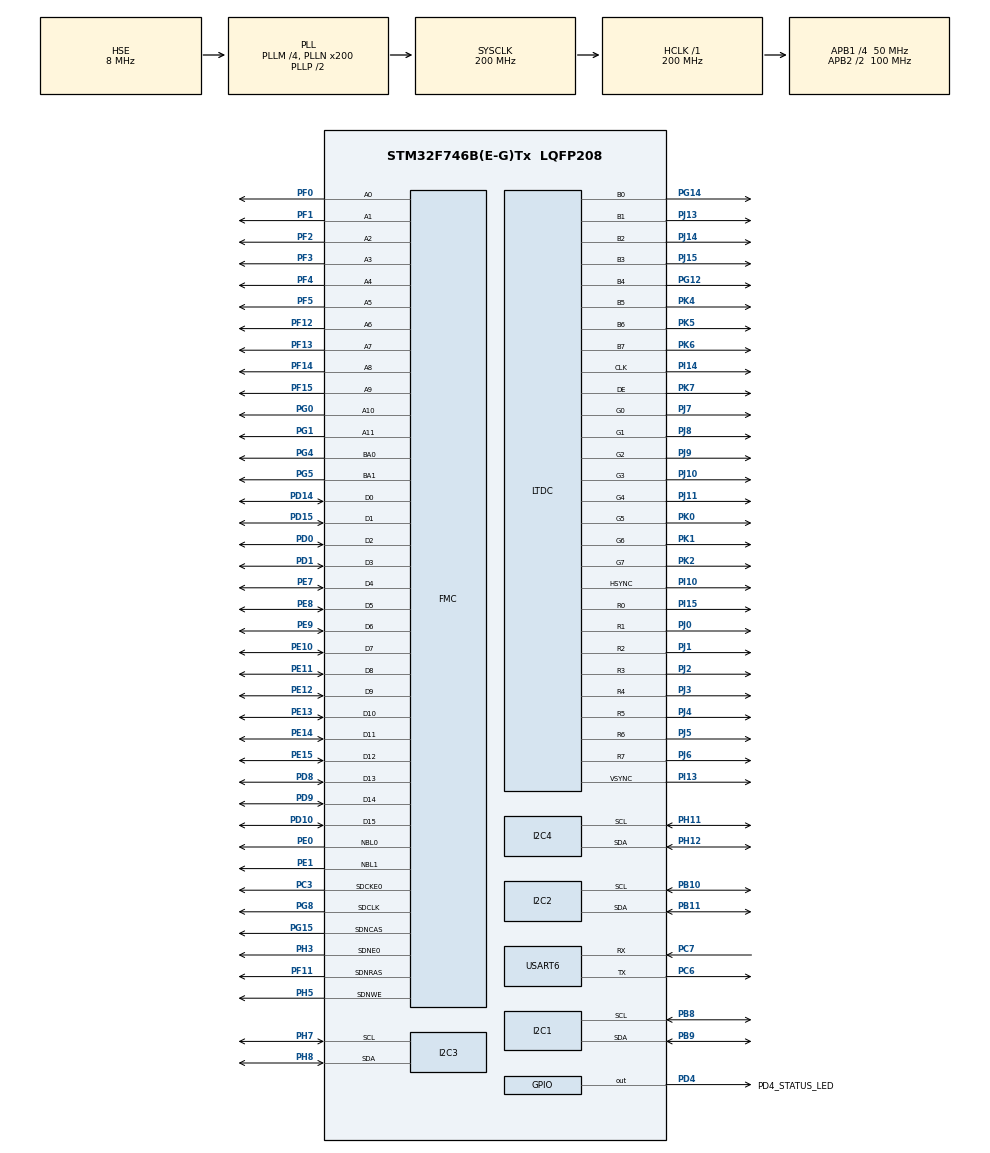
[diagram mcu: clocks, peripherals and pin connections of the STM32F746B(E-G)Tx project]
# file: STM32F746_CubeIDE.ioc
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SH.FMC_D7_DA7.0=FMC_D7,sd-16b-d1
PK5.Signal=LTDC_B6
PJ9.Mode=RGB888
PH12.Signal=I2C4_SDA
FMC.RCDDelay1=2
FMC.SDClockPeriod1=FMC_SDRAM_CLOCK_PERIOD_2
SH.FMC_A0.0=FMC_A0,12b-sda1
PB10.Mode=I2C
PK0.Mode=RGB888
PG4.Signal=FMC_A14_BA0
PG8.Signal=FMC_SDCLK
PG0.Signal=FMC_A10
FMC.LoadToActiveDelay1=2
PK1.Signal=LTDC_G6
SH.FMC_D5_DA5.0=FMC_D5,sd-16b-d1
RCC.SYSCLKSource=RCC_SYSCLKSOURCE_PLLCLK
PJ10.Signal=LTDC_G3
SH.FMC_A15_BA1.0=FMC_BA1,FourSdramBanks1
SH.FMC_D9_DA9.0=FMC_D9,sd-16b-d1
PH5.Signal=FMC_SDNWE
SH.FMC_SDNWE.0=FMC_SDNWE,12b-sda1
I2C4.Timing=0x00C0EAFF
SH.FMC_D11_DA11.0=FMC_D11,sd-16b-d1
PJ5.Mode=RGB888
PD4.Signal=GPIO_Output
RCC.APB2TimFreq_Value=200000000
PC7.Signal=USART6_RX
PH1/OSC_OUT.Signal=RCC_OSC_OUT
PC3.Signal=FMC_SDCKE0
PD0.Signal=FMC_D2_DA2
PD8.Signal=FMC_D13_DA13
USART6.VirtualMode-Asynchronous=VM_ASYNC
PE1.Signal=FMC_NBL1
PJ14.Mode=RGB888
PG14.Mode=RGB888
FMC.SelfRefreshTime1=4
LTDC.PixelFormat_L0=LTDC_PIXEL_FORMAT_RGB565
PK7.Mode=RGB888
PE9.Signal=FMC_D6_DA6
PJ2.Mode=RGB888
SH.FMC_A2.0=FMC_A2,12b-sda1
SH.FMC_D1_DA1.0=FMC_D1,sd-16b-d1
PF3.Signal=FMC_A3
PE10.Signal=FMC_D7_DA7
LTDC.HSync=1
PJ14.Signal=LTDC_B2
Mcu.Package=LQFP208
PB9.Signal=I2C1_SDA
PH12.Mode=I2C
PH11.Mode=I2C
PJ4.Signal=LTDC_R5
FMC.WriteRecoveryTime1=3
SH.FMC_A1.0=FMC_A1,12b-sda1
RCC.APB2CLKDivider=RCC_HCLK_DIV2
SH.FMC_SDCLK.0=FMC_SDCLK,12b-sda1
LTDC.VSync=10
PF14.Signal=FMC_A8
RCC.APB1TimFreq_Value=100000000
VP_DMA2D_VS_DMA2D.Mode=DMA2D_Activate
FMC.RowCycleDelay1=7
PJ13.Mode=RGB888
PH8.Mode=I2C
PJ1.Mode=RGB888
PD15.Signal=FMC_D1_DA1
SH.FMC_D3_DA3.0=FMC_D3,sd-16b-d1
PG12.Signal=LTDC_B4
PK4.Signal=LTDC_B5
SH.FMC_A4.0=FMC_A4,12b-sda1
PG5.Signal=FMC_A15_BA1
SH.FMC_D10_DA10.0=FMC_D10,sd-16b-d1
PI10.Mode=RGB888
PC6.Signal=USART6_TX
PD1.Signal=FMC_D3_DA3
RCC.APB1CLKDivider=RCC_HCLK_DIV4
PJ11.Signal=LTDC_G4
LTDC.ImageWidth_L0=480
PD10.Signal=FMC_D15_DA15
PJ6.Mode=RGB888
SH.FMC_A3.0=FMC_A3,12b-sda1
PJ7.Signal=LTDC_G0
PJ3.Signal=LTDC_R4
FMC.CASLatency1=FMC_SDRAM_CAS_LATENCY_3
PB11.Mode=I2C
SH.FMC_D15_DA15.0=FMC_D15,sd-16b-d1
PC6.Mode=Asynchronous
I2C1.Timing=0x00C0EAFF
PB10.Signal=I2C2_SCL
PJ15.Signal=LTDC_B3
FMC.ReadBurst1=FMC_SDRAM_RBURST_ENABLE
SH.FMC_A6.0=FMC_A6,12b-sda1
PE14.Signal=FMC_D11_DA11
PE15.Signal=FMC_D12_DA12
PE8.Signal=FMC_D5_DA5
PF13.Signal=FMC_A7
SH.FMC_SDNCAS.0=FMC_SDNCAS,12b-sda1
PJ15.Mode=RGB888
PK4.Mode=RGB888
SH.FMC_A5.0=FMC_A5,12b-sda1
LTDC.Alpha_L0=255
PJ8.Signal=LTDC_G1
ProjectManager.HeapSize=0x200
PJ10.Mode=RGB888
NVIC.PriorityGroup=NVIC_PRIORITYGROUP_4
PB8.Mode=I2C
PJ4.Mode=RGB888
PF4.Signal=FMC_A4
Mcu.Family=STM32F7
PC3.Mode=SdramChipSelect1_1
PK7.Signal=LTDC_DE
LTDC.BlendingFactor1_L0=LTDC_BLENDING_FACTOR1_PAxCA
SH.FMC_A8.0=FMC_A8,12b-sda1
RCC.CortexFreq_Value=200000000
SH.FMC_D14_DA14.0=FMC_D14,sd-16b-d1
LTDC.HBP=43
I2C2.Timing=0x00C0EAFF
SH.FMC_NBL0.0=FMC_NBL0,Sd2ByteEnable1
SH.FMC_D6_DA6.0=FMC_D6,sd-16b-d1
SH.FMC_A14_BA0.0=FMC_BA0,FourSdramBanks1
SH.FMC_A11.0=FMC_A11,12b-sda1
PB11.Signal=I2C2_SDA
PG15.Signal=FMC_SDNCAS
ProjectManager.StackSize=0x400
PH3.Mode=SdramChipSelect1_1
PJ6.Signal=LTDC_R7
SH.FMC_A7.0=FMC_A7,12b-sda1
PJ2.Signal=LTDC_R3
PH0/OSC_IN.Mode=HSE-External-Oscillator
RCC.HCLKFreq_Value=200000000
SH.FMC_NBL1.0=FMC_NBL1,Sd2ByteEnable1
LTDC.WindowX1_L0=480
PF12.Signal=FMC_A6
PK2.Mode=RGB888
PI13.Signal=LTDC_VSYNC
SH.FMC_A10.0=FMC_A10,12b-sda1
RCC.AHBFreq_Value=200000000
RCC.HSE_VALUE=8000000
SH.FMC_D8_DA8.0=FMC_D8,sd-16b-d1
FMC.ExitSelfRefreshDelay1=7
FMC.RPDelay1=2
PI14.Mode=RGB888
SH.FMC_D2_DA2.0=FMC_D2,sd-16b-d1
LTDC.VBP=12
PE13.Signal=FMC_D10_DA10
PK6.Mode=RGB888
PF11.Signal=FMC_SDNRAS
LTDC.HFP=8
LTDC.BlendingFactor2_L0=LTDC_BLENDING_FACTOR2_PAxCA
SH.FMC_SDNRAS.0=FMC_SDNRAS,12b-sda1
LTDC.ActiveW=480
PH1/OSC_OUT.Mode=HSE-External-Oscillator
PH7.Mode=I2C
PJ0.Mode=RGB888
SH.FMC_D0_DA0.0=FMC_D0,sd-16b-d1
PJ9.Signal=LTDC_G2
NVIC.LTDC_ER_IRQn=true\:0\:0\:false\:false\:true\:true\:true
SH.FMC_A9.0=FMC_A9,12b-sda1
PJ1.Signal=LTDC_R2
SH.FMC_D4_DA4.0=FMC_D4,sd-16b-d1
PF5.Signal=FMC_A5
I2C3.Timing=0x00C0EAFF
PH7.Signal=I2C3_SCL
PJ7.Mode=RGB888
PF0.Signal=FMC_A0
PE7.Signal=FMC_D4_DA4
PI15.Mode=RGB888
PK1.Mode=RGB888
RCC.PLLSourceVirtual=RCC_PLLSOURCE_HSE
PK6.Signal=LTDC_B7
NVIC.LTDC_IRQn=true\:0\:0\:false\:false\:true\:true\:true
PK2.Signal=LTDC_G7
LTDC.VFP=4
LTDC.WindowY1_L0=272
PJ8.Mode=RGB888
PH11.Signal=I2C4_SCL
PG1.Signal=FMC_A11
PI14.Signal=LTDC_CLK
PI10.Signal=LTDC_HSYNC
PD9.Signal=FMC_D14_DA14
PJ11.Mode=RGB888
ProjectManager.TargetToolchain=STM32CubeIDE
SH.FMC_D13_DA13.0=FMC_D13,sd-16b-d1
LTDC.ActiveH=272
PH8.Signal=I2C3_SDA
PB9.Mode=I2C
PF2.Signal=FMC_A2
RCC.USBFreq_Value=200000000
PE11.Signal=FMC_D8_DA8
RCC.LSE_VALUE=32768
PK0.Signal=LTDC_G5
PK5.Mode=RGB888
PG14.Signal=LTDC_B0
board=custom
PG12.Mode=RGB888
RCC.VCOOutputFreq_Value=400000000
PJ3.Mode=RGB888
PH0/OSC_IN.Signal=RCC_OSC_IN
RCC.APB2Freq_Value=100000000
LTDC.Layers=0
PD4.GPIO_Label=PD4_STATUS_LED
SH.FMC_D12_DA12.0=FMC_D12,sd-16b-d1
PF15.Signal=FMC_A9
PF1.Signal=FMC_A1
PI13.Mode=RGB888
PJ0.Signal=LTDC_R1
Mcu.Name=STM32F746B(E-G)Tx
PE0.Signal=FMC_NBL0
PE12.Signal=FMC_D9_DA9
PD14.Signal=FMC_D0_DA0
RCC.SYSCLKFreq_VALUE=200000000
PJ5.Signal=LTDC_R6
RCC.HSI_VALUE=16000000
PH3.Signal=FMC_SDNE0
RCC.PLLM=4
RCC.PLLN=200
PI15.Signal=LTDC_R0
PB8.Signal=I2C1_SCL
PC7.Mode=Asynchronous
RCC.APB1Freq_Value=50000000
VP_CRC_VS_CRC.Mode=CRC_Activate
LTDC.ImageHeight_L0=272
PJ13.Signal=LTDC_B1

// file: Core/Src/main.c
/* USER CODE BEGIN Header */
/**
  ******************************************************************************
  * @file           : main.c
  * @brief          : Main program body
  ******************************************************************************
  * @attention
  *
  * <h2><center>&copy; Copyright (c) 2021 STMicroelectronics.
  * All rights reserved.</center></h2>
  *
  * This software component is licensed by ST under BSD 3-Clause license,
  * the "License"; You may not use this file except in compliance with the
  * License. You may obtain a copy of the License at:
  *                        opensource.org/licenses/BSD-3-Clause
  *
  ******************************************************************************
  */
/* USER CODE END Header */
#include "main.h"

CRC_HandleTypeDef hcrc;

DMA2D_HandleTypeDef hdma2d;

I2C_HandleTypeDef hi2c1;
I2C_HandleTypeDef hi2c2;
I2C_HandleTypeDef hi2c3;
I2C_HandleTypeDef hi2c4;

LTDC_HandleTypeDef hltdc;

UART_HandleTypeDef huart6;

SDRAM_HandleTypeDef hsdram1;

void SystemClock_Config(void);
static void MX_GPIO_Init(void);
static void MX_CRC_Init(void);
static void MX_DMA2D_Init(void);
static void MX_LTDC_Init(void);
static void MX_I2C1_Init(void);
static void MX_I2C2_Init(void);
static void MX_I2C3_Init(void);
static void MX_I2C4_Init(void);
static void MX_USART6_UART_Init(void);
static void MX_FMC_Init(void);

int main(void)
{

  /* MCU Configuration--------------------------------------------------------*/

  /* Reset of all peripherals, Initializes the Flash interface and the Systick. */
  HAL_Init();

  /* Configure the system clock */
  SystemClock_Config();

  /* Initialize all configured peripherals */
  MX_GPIO_Init();
  MX_CRC_Init();
  MX_DMA2D_Init();
  MX_LTDC_Init();
  MX_I2C1_Init();
  MX_I2C2_Init();
  MX_I2C3_Init();
  MX_I2C4_Init();
  MX_USART6_UART_Init();
  MX_FMC_Init();

  /* Infinite loop */
  /* USER CODE BEGIN WHILE */
  while (1)
  {
	  HAL_GPIO_TogglePin(PD4_STATUS_LED_GPIO_Port, PD4_STATUS_LED_Pin);
	  HAL_Delay(500);
    /* USER CODE END WHILE */

  }
}

void SystemClock_Config(void)
{
  RCC_OscInitTypeDef RCC_OscInitStruct = {0};
  RCC_ClkInitTypeDef RCC_ClkInitStruct = {0};
  RCC_PeriphCLKInitTypeDef PeriphClkInitStruct = {0};

  /** Configure the main internal regulator output voltage
  */
  __HAL_RCC_PWR_CLK_ENABLE();
  __HAL_PWR_VOLTAGESCALING_CONFIG(PWR_REGULATOR_VOLTAGE_SCALE1);
  /** Initializes the RCC Oscillators according to the specified parameters
  * in the RCC_OscInitTypeDef structure.
  */
  RCC_OscInitStruct.OscillatorType = RCC_OSCILLATORTYPE_HSE;
  RCC_OscInitStruct.HSEState = RCC_HSE_ON;
  RCC_OscInitStruct.PLL.PLLState = RCC_PLL_ON;
  RCC_OscInitStruct.PLL.PLLSource = RCC_PLLSOURCE_HSE;
  RCC_OscInitStruct.PLL.PLLM = 4;
  RCC_OscInitStruct.PLL.PLLN = 200;
  RCC_OscInitStruct.PLL.PLLP = RCC_PLLP_DIV2;
  RCC_OscInitStruct.PLL.PLLQ = 2;
  if (HAL_RCC_OscConfig(&RCC_OscInitStruct) != HAL_OK)
  {
    Error_Handler();
  }
  /** Activate the Over-Drive mode
  */
  if (HAL_PWREx_EnableOverDrive() != HAL_OK)
  {
    Error_Handler();
  }
  /** Initializes the CPU, AHB and APB buses clocks
  */
  RCC_ClkInitStruct.ClockType = RCC_CLOCKTYPE_HCLK|RCC_CLOCKTYPE_SYSCLK
                              |RCC_CLOCKTYPE_PCLK1|RCC_CLOCKTYPE_PCLK2;
  RCC_ClkInitStruct.SYSCLKSource = RCC_SYSCLKSOURCE_PLLCLK;
  RCC_ClkInitStruct.AHBCLKDivider = RCC_SYSCLK_DIV1;
  RCC_ClkInitStruct.APB1CLKDivider = RCC_HCLK_DIV4;
  RCC_ClkInitStruct.APB2CLKDivider = RCC_HCLK_DIV2;

  if (HAL_RCC_ClockConfig(&RCC_ClkInitStruct, FLASH_LATENCY_6) != HAL_OK)
  {
    Error_Handler();
  }
  PeriphClkInitStruct.PeriphClockSelection = RCC_PERIPHCLK_LTDC|RCC_PERIPHCLK_USART6
                              |RCC_PERIPHCLK_I2C1|RCC_PERIPHCLK_I2C2
                              |RCC_PERIPHCLK_I2C3|RCC_PERIPHCLK_I2C4;
  PeriphClkInitStruct.PLLSAI.PLLSAIN = 192;
  PeriphClkInitStruct.PLLSAI.PLLSAIR = 2;
  PeriphClkInitStruct.PLLSAI.PLLSAIQ = 2;
  PeriphClkInitStruct.PLLSAI.PLLSAIP = RCC_PLLSAIP_DIV2;
  PeriphClkInitStruct.PLLSAIDivQ = 1;
  PeriphClkInitStruct.PLLSAIDivR = RCC_PLLSAIDIVR_2;
  PeriphClkInitStruct.Usart6ClockSelection = RCC_USART6CLKSOURCE_PCLK2;
  PeriphClkInitStruct.I2c1ClockSelection = RCC_I2C1CLKSOURCE_PCLK1;
  PeriphClkInitStruct.I2c2ClockSelection = RCC_I2C2CLKSOURCE_PCLK1;
  PeriphClkInitStruct.I2c3ClockSelection = RCC_I2C3CLKSOURCE_PCLK1;
  PeriphClkInitStruct.I2c4ClockSelection = RCC_I2C4CLKSOURCE_PCLK1;
  if (HAL_RCCEx_PeriphCLKConfig(&PeriphClkInitStruct) != HAL_OK)
  {
    Error_Handler();
  }
}

static void MX_CRC_Init(void)
{

  hcrc.Instance = CRC;
  hcrc.Init.DefaultPolynomialUse = DEFAULT_POLYNOMIAL_ENABLE;
  hcrc.Init.DefaultInitValueUse = DEFAULT_INIT_VALUE_ENABLE;
  hcrc.Init.InputDataInversionMode = CRC_INPUTDATA_INVERSION_NONE;
  hcrc.Init.OutputDataInversionMode = CRC_OUTPUTDATA_INVERSION_DISABLE;
  hcrc.InputDataFormat = CRC_INPUTDATA_FORMAT_BYTES;
  if (HAL_CRC_Init(&hcrc) != HAL_OK)
  {
    Error_Handler();
  }

}

static void MX_DMA2D_Init(void)
{

  hdma2d.Instance = DMA2D;
  hdma2d.Init.Mode = DMA2D_M2M;
  hdma2d.Init.ColorMode = DMA2D_OUTPUT_ARGB8888;
  hdma2d.Init.OutputOffset = 0;
  hdma2d.LayerCfg[1].InputOffset = 0;
  hdma2d.LayerCfg[1].InputColorMode = DMA2D_INPUT_ARGB8888;
  hdma2d.LayerCfg[1].AlphaMode = DMA2D_NO_MODIF_ALPHA;
  hdma2d.LayerCfg[1].InputAlpha = 0;
  if (HAL_DMA2D_Init(&hdma2d) != HAL_OK)
  {
    Error_Handler();
  }
  if (HAL_DMA2D_ConfigLayer(&hdma2d, 1) != HAL_OK)
  {
    Error_Handler();
  }

}

static void MX_I2C1_Init(void)
{

  hi2c1.Instance = I2C1;
  hi2c1.Init.Timing = 0x00C0EAFF;
  hi2c1.Init.OwnAddress1 = 0;
  hi2c1.Init.AddressingMode = I2C_ADDRESSINGMODE_7BIT;
  hi2c1.Init.DualAddressMode = I2C_DUALADDRESS_DISABLE;
  hi2c1.Init.OwnAddress2 = 0;
  hi2c1.Init.OwnAddress2Masks = I2C_OA2_NOMASK;
  hi2c1.Init.GeneralCallMode = I2C_GENERALCALL_DISABLE;
  hi2c1.Init.NoStretchMode = I2C_NOSTRETCH_DISABLE;
  if (HAL_I2C_Init(&hi2c1) != HAL_OK)
  {
    Error_Handler();
  }
  /** Configure Analogue filter
  */
  if (HAL_I2CEx_ConfigAnalogFilter(&hi2c1, I2C_ANALOGFILTER_ENABLE) != HAL_OK)
  {
    Error_Handler();
  }
  /** Configure Digital filter
  */
  if (HAL_I2CEx_ConfigDigitalFilter(&hi2c1, 0) != HAL_OK)
  {
    Error_Handler();
  }

}

static void MX_I2C2_Init(void)
{

  hi2c2.Instance = I2C2;
  hi2c2.Init.Timing = 0x00C0EAFF;
  hi2c2.Init.OwnAddress1 = 0;
  hi2c2.Init.AddressingMode = I2C_ADDRESSINGMODE_7BIT;
  hi2c2.Init.DualAddressMode = I2C_DUALADDRESS_DISABLE;
  hi2c2.Init.OwnAddress2 = 0;
  hi2c2.Init.OwnAddress2Masks = I2C_OA2_NOMASK;
  hi2c2.Init.GeneralCallMode = I2C_GENERALCALL_DISABLE;
  hi2c2.Init.NoStretchMode = I2C_NOSTRETCH_DISABLE;
  if (HAL_I2C_Init(&hi2c2) != HAL_OK)
  {
    Error_Handler();
  }
  /** Configure Analogue filter
  */
  if (HAL_I2CEx_ConfigAnalogFilter(&hi2c2, I2C_ANALOGFILTER_ENABLE) != HAL_OK)
  {
    Error_Handler();
  }
  /** Configure Digital filter
  */
  if (HAL_I2CEx_ConfigDigitalFilter(&hi2c2, 0) != HAL_OK)
  {
    Error_Handler();
  }

}

static void MX_I2C3_Init(void)
{

  hi2c3.Instance = I2C3;
  hi2c3.Init.Timing = 0x00C0EAFF;
  hi2c3.Init.OwnAddress1 = 0;
  hi2c3.Init.AddressingMode = I2C_ADDRESSINGMODE_7BIT;
  hi2c3.Init.DualAddressMode = I2C_DUALADDRESS_DISABLE;
  hi2c3.Init.OwnAddress2 = 0;
  hi2c3.Init.OwnAddress2Masks = I2C_OA2_NOMASK;
  hi2c3.Init.GeneralCallMode = I2C_GENERALCALL_DISABLE;
  hi2c3.Init.NoStretchMode = I2C_NOSTRETCH_DISABLE;
  if (HAL_I2C_Init(&hi2c3) != HAL_OK)
  {
    Error_Handler();
  }
  /** Configure Analogue filter
  */
  if (HAL_I2CEx_ConfigAnalogFilter(&hi2c3, I2C_ANALOGFILTER_ENABLE) != HAL_OK)
  {
    Error_Handler();
  }
  /** Configure Digital filter
  */
  if (HAL_I2CEx_ConfigDigitalFilter(&hi2c3, 0) != HAL_OK)
  {
    Error_Handler();
  }

}

static void MX_I2C4_Init(void)
{

  hi2c4.Instance = I2C4;
  hi2c4.Init.Timing = 0x00C0EAFF;
  hi2c4.Init.OwnAddress1 = 0;
  hi2c4.Init.AddressingMode = I2C_ADDRESSINGMODE_7BIT;
  hi2c4.Init.DualAddressMode = I2C_DUALADDRESS_DISABLE;
  hi2c4.Init.OwnAddress2 = 0;
  hi2c4.Init.OwnAddress2Masks = I2C_OA2_NOMASK;
  hi2c4.Init.GeneralCallMode = I2C_GENERALCALL_DISABLE;
  hi2c4.Init.NoStretchMode = I2C_NOSTRETCH_DISABLE;
  if (HAL_I2C_Init(&hi2c4) != HAL_OK)
  {
    Error_Handler();
  }
  /** Configure Analogue filter
  */
  if (HAL_I2CEx_ConfigAnalogFilter(&hi2c4, I2C_ANALOGFILTER_ENABLE) != HAL_OK)
  {
    Error_Handler();
  }
  /** Configure Digital filter
  */
  if (HAL_I2CEx_ConfigDigitalFilter(&hi2c4, 0) != HAL_OK)
  {
    Error_Handler();
  }

}

static void MX_LTDC_Init(void)
{

  LTDC_LayerCfgTypeDef pLayerCfg = {0};

  hltdc.Instance = LTDC;
  hltdc.Init.HSPolarity = LTDC_HSPOLARITY_AL;
  hltdc.Init.VSPolarity = LTDC_VSPOLARITY_AL;
  hltdc.Init.DEPolarity = LTDC_DEPOLARITY_AL;
  hltdc.Init.PCPolarity = LTDC_PCPOLARITY_IPC;
  hltdc.Init.HorizontalSync = 0;
  hltdc.Init.VerticalSync = 9;
  hltdc.Init.AccumulatedHBP = 43;
  hltdc.Init.AccumulatedVBP = 21;
  hltdc.Init.AccumulatedActiveW = 523;
  hltdc.Init.AccumulatedActiveH = 293;
  hltdc.Init.TotalWidth = 531;
  hltdc.Init.TotalHeigh = 297;
  hltdc.Init.Backcolor.Blue = 0;
  hltdc.Init.Backcolor.Green = 0;
  hltdc.Init.Backcolor.Red = 0;
  if (HAL_LTDC_Init(&hltdc) != HAL_OK)
  {
    Error_Handler();
  }
  pLayerCfg.WindowX0 = 0;
  pLayerCfg.WindowX1 = 480;
  pLayerCfg.WindowY0 = 0;
  pLayerCfg.WindowY1 = 272;
  pLayerCfg.PixelFormat = LTDC_PIXEL_FORMAT_RGB565;
  pLayerCfg.Alpha = 255;
  pLayerCfg.Alpha0 = 0;
  pLayerCfg.BlendingFactor1 = LTDC_BLENDING_FACTOR1_PAxCA;
  pLayerCfg.BlendingFactor2 = LTDC_BLENDING_FACTOR2_PAxCA;
  pLayerCfg.FBStartAdress = 0;
  pLayerCfg.ImageWidth = 480;
  pLayerCfg.ImageHeight = 272;
  pLayerCfg.Backcolor.Blue = 0;
  pLayerCfg.Backcolor.Green = 0;
  pLayerCfg.Backcolor.Red = 0;
  if (HAL_LTDC_ConfigLayer(&hltdc, &pLayerCfg, 0) != HAL_OK)
  {
    Error_Handler();
  }

}

static void MX_USART6_UART_Init(void)
{

  huart6.Instance = USART6;
  huart6.Init.BaudRate = 115200;
  huart6.Init.WordLength = UART_WORDLENGTH_8B;
  huart6.Init.StopBits = UART_STOPBITS_1;
  huart6.Init.Parity = UART_PARITY_NONE;
  huart6.Init.Mode = UART_MODE_TX_RX;
  huart6.Init.HwFlowCtl = UART_HWCONTROL_NONE;
  huart6.Init.OverSampling = UART_OVERSAMPLING_16;
  huart6.Init.OneBitSampling = UART_ONE_BIT_SAMPLE_DISABLE;
  huart6.AdvancedInit.AdvFeatureInit = UART_ADVFEATURE_NO_INIT;
  if (HAL_UART_Init(&huart6) != HAL_OK)
  {
    Error_Handler();
  }

}

/* FMC initialization function */
static void MX_FMC_Init(void)
{

  FMC_SDRAM_TimingTypeDef SdramTiming = {0};

  /** Perform the SDRAM1 memory initialization sequence
  */
  hsdram1.Instance = FMC_SDRAM_DEVICE;
  /* hsdram1.Init */
  hsdram1.Init.SDBank = FMC_SDRAM_BANK1;
  hsdram1.Init.ColumnBitsNumber = FMC_SDRAM_COLUMN_BITS_NUM_8;
  hsdram1.Init.RowBitsNumber = FMC_SDRAM_ROW_BITS_NUM_12;
  hsdram1.Init.MemoryDataWidth = FMC_SDRAM_MEM_BUS_WIDTH_16;
  hsdram1.Init.InternalBankNumber = FMC_SDRAM_INTERN_BANKS_NUM_4;
  hsdram1.Init.CASLatency = FMC_SDRAM_CAS_LATENCY_3;
  hsdram1.Init.WriteProtection = FMC_SDRAM_WRITE_PROTECTION_DISABLE;
  hsdram1.Init.SDClockPeriod = FMC_SDRAM_CLOCK_PERIOD_2;
  hsdram1.Init.ReadBurst = FMC_SDRAM_RBURST_ENABLE;
  hsdram1.Init.ReadPipeDelay = FMC_SDRAM_RPIPE_DELAY_0;
  /* SdramTiming */
  SdramTiming.LoadToActiveDelay = 2;
  SdramTiming.ExitSelfRefreshDelay = 7;
  SdramTiming.SelfRefreshTime = 4;
  SdramTiming.RowCycleDelay = 7;
  SdramTiming.WriteRecoveryTime = 3;
  SdramTiming.RPDelay = 2;
  SdramTiming.RCDDelay = 2;

  if (HAL_SDRAM_Init(&hsdram1, &SdramTiming) != HAL_OK)
  {
    Error_Handler( );
  }

}

static void MX_GPIO_Init(void)
{
  GPIO_InitTypeDef GPIO_InitStruct = {0};

  /* GPIO Ports Clock Enable */
  __HAL_RCC_GPIOI_CLK_ENABLE();
  __HAL_RCC_GPIOF_CLK_ENABLE();
  __HAL_RCC_GPIOH_CLK_ENABLE();
  __HAL_RCC_GPIOC_CLK_ENABLE();
  __HAL_RCC_GPIOJ_CLK_ENABLE();
  __HAL_RCC_GPIOG_CLK_ENABLE();
  __HAL_RCC_GPIOE_CLK_ENABLE();
  __HAL_RCC_GPIOB_CLK_ENABLE();
  __HAL_RCC_GPIOD_CLK_ENABLE();
  __HAL_RCC_GPIOK_CLK_ENABLE();

  /*Configure GPIO pin Output Level */
  HAL_GPIO_WritePin(PD4_STATUS_LED_GPIO_Port, PD4_STATUS_LED_Pin, GPIO_PIN_RESET);

  /*Configure GPIO pin : PD4_STATUS_LED_Pin */
  GPIO_InitStruct.Pin = PD4_STATUS_LED_Pin;
  GPIO_InitStruct.Mode = GPIO_MODE_OUTPUT_PP;
  GPIO_InitStruct.Pull = GPIO_NOPULL;
  GPIO_InitStruct.Speed = GPIO_SPEED_FREQ_LOW;
  HAL_GPIO_Init(PD4_STATUS_LED_GPIO_Port, &GPIO_InitStruct);

}

void Error_Handler(void)
{
  __disable_irq();
  while (1)
  {
  }
}

/************************ (C) COPYRIGHT STMicroelectronics *****END OF FILE****/
